[part 1 of 3: packages /EcuInstances to /CommunicationClusters]
AUTOSAR XML (schema 4-2-2)
package /EcuInstances
  ecu instance SRS3: associated-com-i-pdu-group=[RxMPG_ZCUD_CAN1, TxMPG_ZCUD_CAN1, TxMPG_ZCUD_CANFD3], com-configuration-gw-time-base=0.005, com-configuration-rx-time-base=0.005, com-configuration-tx-time-base=0.005, sleep-mode-supported=true, wake-up-over-bus-supported=true
    can communication controller ZCUD_CAN1: wake-up-by-controller-supported=true, can-controller-attributes=can-controller-configuration-requirements={max-number-of-time-quanta-per-bit=22, max-sample-point=86.67, max-sync-jump-width=13.0, min-number-of-time-quanta-per-bit=10, min-sample-point=80.0, min-sync-jump-width=9.0}
    can communication controller ZCUD_CANFD3: can-controller-attributes=can-controller-configuration-requirements={can-controller-fd-requirements={max-number-of-time-quanta-per-bit=40, max-sample-point=70.0, max-sync-jump-width=30.0, min-number-of-time-quanta-per-bit=20, min-sample-point=70.0, min-sync-jump-width=30.0}, max-number-of-time-quanta-per-bit=22, max-sample-point=86.67, max-sync-jump-width=13.0, min-number-of-time-quanta-per-bit=10, min-sample-point=80.0, min-sync-jump-width=9.0}
    can communication connector ZCUD_CAN1_SRS3: comm-controller=ZCUD_CAN1, pnc-wakeup-data-mask=536870912
    can communication connector ZCUD_CANFD3_SRS3: comm-controller=ZCUD_CANFD3, pnc-gateway-type=NONE, pnc-wakeup-data-mask=536870912
package /CommunicationClusters
  can cluster ZCUD_CANFD3: baudrate=500000, protocol-name=CAN, protocol-version=CAN, can-fd-baudrate=2000000
    can physical channel ZCUD_CANFD3: comm-connectors=ZCUD_CANFD3_SRS3
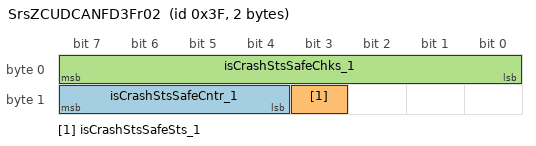
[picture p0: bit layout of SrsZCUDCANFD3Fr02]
      frame SrsZCUDCANFD3Fr02: id 0x3F, from SRS3, frame-length=2, can-addressing-mode=STANDARD, can-fd-frame-support=true, can-frame-tx-behavior=CAN-FD
        pdu SrsZCUDCANFD3SignalIPdu02: length=2, minimum-delay=0.01, transmission-mode-condition{data-filter=data-filter-type=ALWAYS, i-signal-in-i-pdu=igCrashStsSafe_1_mtx}, transmission-mode-true-timing={cyclic-timing={time-offset=0.0, time-period=0.2}, event-controlled-timing=number-of-repetitions=0}, unused-bit-pattern=0
          signal isCrashStsSafeCntr_1: start 15, 4 bit, big-endian, data-type-policy=NETWORK-REPRESENTATION-FROM-COM-SPEC, init-value=0, base-type=UInt4_2, compu-method=UInt4_1, category=VALUE, transfer-property=TRIGGERED  # Counter for E2E
          signal isCrashStsSafeSts_1: start 11, 1 bit, big-endian, data-type-policy=NETWORK-REPRESENTATION-FROM-COM-SPEC, init-value=0, base-type=CrashSts2_2, compu-method=CrashSts2_2, category=VALUE, transfer-property=TRIGGERED  # Information if a crash has been detected by SRS.
          signal isCrashStsSafeChks_1: start 7, 8 bit, big-endian, data-type-policy=NETWORK-REPRESENTATION-FROM-COM-SPEC, init-value=255, base-type=UInt8_2, compu-method=UInt8_1, category=VALUE, transfer-property=TRIGGERED  # Checksum for E2E
          mapping igCrashStsSafe_1_mtx: i-signal-group=igCrashStsSafe_1, packing-byte-order=big-endian, start-position=7, transfer-property=TRIGGERED, update-indication-bit-position=10
      frame SrsZCUDCANFD3VFCVectorFr: id 0x546, from SRS3, frame-length=8, can-addressing-mode=STANDARD, can-fd-frame-support=false, can-frame-tx-behavior=CAN-20
        pdu SrsZCUDCANFD3VFCVectorSignalIPdu: length=8, transmission-mode-condition{data-filter=data-filter-type=ALWAYS, i-signal-in-i-pdu=igVFCVectorSRS_1_mtx}, transmission-mode-true-timing=cyclic-timing={time-offset=0.0, time-period=1.0}, unused-bit-pattern=0
          signal isVFCVectorSRSVFCid9_1: start 12, 1 bit, big-endian, data-type-policy=NETWORK-REPRESENTATION-FROM-COM-SPEC, init-value=0, base-type=VFCOnOff_4, compu-method=VFCOnOff_4, category=VALUE, transfer-property=PENDING  # IPWakeup
          signal isVFCVectorSRSVFCid58_1: start 59, 1 bit, big-endian, data-type-policy=NETWORK-REPRESENTATION-FROM-COM-SPEC, init-value=0, base-type=VFCOnOff_4, compu-method=VFCOnOff_4, category=VALUE, transfer-property=PENDING  # VFC58
          signal isVFCVectorSRSVFCid56_1: start 61, 1 bit, big-endian, data-type-policy=NETWORK-REPRESENTATION-FROM-COM-SPEC, init-value=0, base-type=VFCOnOff_4, compu-method=VFCOnOff_4, category=VALUE, transfer-property=PENDING  # BackboneFlexray
          signal isVFCVectorSRSVFCid41_1: start 44, 1 bit, big-endian, data-type-policy=NETWORK-REPRESENTATION-FROM-COM-SPEC, init-value=0, base-type=VFCOnOff_4, compu-method=VFCOnOff_4, category=VALUE, transfer-property=PENDING  # InfotainmentPush
          signal isVFCVectorSRSVFCid34_1: start 35, 1 bit, big-endian, data-type-policy=NETWORK-REPRESENTATION-FROM-COM-SPEC, init-value=0, base-type=VFCOnOff_4, compu-method=VFCOnOff_4, category=VALUE, transfer-property=PENDING  # VehicleModeManagement
          signal isVFCVectorSRSVFCid2_1: start 3, 1 bit, big-endian, data-type-policy=NETWORK-REPRESENTATION-FROM-COM-SPEC, init-value=0, base-type=VFCOnOff_4, compu-method=VFCOnOff_4, category=VALUE, transfer-property=PENDING  # PostClimatisation
          signal isVFCVectorSRSVFCid50_1: start 51, 1 bit, big-endian, data-type-policy=NETWORK-REPRESENTATION-FROM-COM-SPEC, init-value=0, base-type=VFCOnOff_4, compu-method=VFCOnOff_4, category=VALUE, transfer-property=PENDING  # VFC50
          signal isVFCVectorSRSVFCid39_1: start 46, 1 bit, big-endian, data-type-policy=NETWORK-REPRESENTATION-FROM-COM-SPEC, init-value=0, base-type=VFCOnOff_4, compu-method=VFCOnOff_4, category=VALUE, transfer-property=PENDING  # VFC39
          signal isVFCVectorSRSVFCid53_1: start 48, 1 bit, big-endian, data-type-policy=NETWORK-REPRESENTATION-FROM-COM-SPEC, init-value=0, base-type=VFCOnOff_4, compu-method=VFCOnOff_4, category=VALUE, transfer-property=PENDING  # VisualAssist
          signal isVFCVectorSRSVFCid11_1: start 10, 1 bit, big-endian, data-type-policy=NETWORK-REPRESENTATION-FROM-COM-SPEC, init-value=0, base-type=VFCOnOff_4, compu-method=VFCOnOff_4, category=VALUE, transfer-property=PENDING  # VFC11
          signal isVFCVectorSRSVFCid45_1: start 40, 1 bit, big-endian, data-type-policy=NETWORK-REPRESENTATION-FROM-COM-SPEC, init-value=0, base-type=VFCOnOff_4, compu-method=VFCOnOff_4, category=VALUE, transfer-property=PENDING  # GlobalShortDuration
          signal isVFCVectorSRSVFCid3_1: start 2, 1 bit, big-endian, data-type-policy=NETWORK-REPRESENTATION-FROM-COM-SPEC, init-value=0, base-type=VFCOnOff_4, compu-method=VFCOnOff_4, category=VALUE, transfer-property=PENDING  # PowertrainParkingClimatization
          signal isVFCVectorSRSVFCid10_1: start 11, 1 bit, big-endian, data-type-policy=NETWORK-REPRESENTATION-FROM-COM-SPEC, init-value=0, base-type=VFCOnOff_4, compu-method=VFCOnOff_4, category=VALUE, transfer-property=PENDING  # ExteriorLighting
          signal isVFCVectorSRSVFCid25_1: start 28, 1 bit, big-endian, data-type-policy=NETWORK-REPRESENTATION-FROM-COM-SPEC, init-value=0, base-type=VFCOnOff_4, compu-method=VFCOnOff_4, category=VALUE, transfer-property=PENDING  # SeatComfortFunctions
          signal isVFCVectorSRSVFCid5_1: start 0, 1 bit, big-endian, data-type-policy=NETWORK-REPRESENTATION-FROM-COM-SPEC, init-value=0, base-type=VFCOnOff_4, compu-method=VFCOnOff_4, category=VALUE, transfer-property=PENDING  # VFC5
          signal isVFCVectorSRSVFCid21_1: start 16, 1 bit, big-endian, data-type-policy=NETWORK-REPRESENTATION-FROM-COM-SPEC, init-value=0, base-type=VFCOnOff_4, compu-method=VFCOnOff_4, category=VALUE, transfer-property=PENDING  # PowerClosures
          signal isVFCVectorSRSVFCid12_1: start 9, 1 bit, big-endian, data-type-policy=NETWORK-REPRESENTATION-FROM-COM-SPEC, init-value=0, base-type=VFCOnOff_4, compu-method=VFCOnOff_4, category=VALUE, transfer-property=PENDING  # Alarm
          signal isVFCVectorSRSVFCid54_1: start 63, 1 bit, big-endian, data-type-policy=NETWORK-REPRESENTATION-FROM-COM-SPEC, init-value=0, base-type=VFCOnOff_4, compu-method=VFCOnOff_4, category=VALUE, transfer-property=PENDING  # PassiveSafety
          signal isVFCVectorSRSVFCid47_1: start 54, 1 bit, big-endian, data-type-policy=NETWORK-REPRESENTATION-FROM-COM-SPEC, init-value=0, base-type=VFCOnOff_4, compu-method=VFCOnOff_4, category=VALUE, transfer-property=PENDING  # VFC47
          signal isVFCVectorSRSVFCid38_1: start 47, 1 bit, big-endian, data-type-policy=NETWORK-REPRESENTATION-FROM-COM-SPEC, init-value=0, base-type=VFCOnOff_4, compu-method=VFCOnOff_4, category=VALUE, transfer-property=PENDING  # Visibility
          signal isVFCVectorSRSVFCid42_1: start 43, 1 bit, big-endian, data-type-policy=NETWORK-REPRESENTATION-FROM-COM-SPEC, init-value=0, base-type=VFCOnOff_4, compu-method=VFCOnOff_4, category=VALUE, transfer-property=PENDING  # ChargingHV
          signal isVFCVectorSRSVFCid52_1: start 49, 1 bit, big-endian, data-type-policy=NETWORK-REPRESENTATION-FROM-COM-SPEC, init-value=0, base-type=VFCOnOff_4, compu-method=VFCOnOff_4, category=VALUE, transfer-property=PENDING  # HVBatteryThermalEventWarning
          signal isVFCVectorSRSVFCid24_1: start 29, 1 bit, big-endian, data-type-policy=NETWORK-REPRESENTATION-FROM-COM-SPEC, init-value=0, base-type=VFCOnOff_4, compu-method=VFCOnOff_4, category=VALUE, transfer-property=PENDING  # SettingsProfile
          signal isVFCVectorSRSVFCid60_1: start 57, 1 bit, big-endian, data-type-policy=NETWORK-REPRESENTATION-FROM-COM-SPEC, init-value=0, base-type=VFCOnOff_4, compu-method=VFCOnOff_4, category=VALUE, transfer-property=PENDING  # VFC60
          signal isVFCVectorSRSVFCid57_1: start 60, 1 bit, big-endian, data-type-policy=NETWORK-REPRESENTATION-FROM-COM-SPEC, init-value=0, base-type=VFCOnOff_4, compu-method=VFCOnOff_4, category=VALUE, transfer-property=PENDING  # Functionmarket
          signal isVFCVectorSRSVFCid49_1: start 52, 1 bit, big-endian, data-type-policy=NETWORK-REPRESENTATION-FROM-COM-SPEC, init-value=0, base-type=VFCOnOff_4, compu-method=VFCOnOff_4, category=VALUE, transfer-property=PENDING  # ChargingLVInit
          signal isVFCVectorSRSVFCid19_1: start 18, 1 bit, big-endian, data-type-policy=NETWORK-REPRESENTATION-FROM-COM-SPEC, init-value=0, base-type=VFCOnOff_4, compu-method=VFCOnOff_4, category=VALUE, transfer-property=PENDING  # VFC19
          signal isVFCVectorSRSVFCid4_1: start 1, 1 bit, big-endian, data-type-policy=NETWORK-REPRESENTATION-FROM-COM-SPEC, init-value=0, base-type=VFCOnOff_4, compu-method=VFCOnOff_4, category=VALUE, transfer-property=PENDING  # VFC4
          signal isVFCVectorSRSVFCid20_1: start 17, 1 bit, big-endian, data-type-policy=NETWORK-REPRESENTATION-FROM-COM-SPEC, init-value=0, base-type=VFCOnOff_4, compu-method=VFCOnOff_4, category=VALUE, transfer-property=PENDING  # VFC20
          signal isVFCVectorSRSVFCid8_1: start 13, 1 bit, big-endian, data-type-policy=NETWORK-REPRESENTATION-FROM-COM-SPEC, init-value=0, base-type=VFCOnOff_4, compu-method=VFCOnOff_4, category=VALUE, transfer-property=PENDING  # VFC8
          signal isVFCVectorSRSVFCid27_1: start 26, 1 bit, big-endian, data-type-policy=NETWORK-REPRESENTATION-FROM-COM-SPEC, init-value=0, base-type=VFCOnOff_4, compu-method=VFCOnOff_4, category=VALUE, transfer-property=PENDING  # InfotainmentPoll
          signal isVFCVectorSRSVFCid29_1: start 24, 1 bit, big-endian, data-type-policy=NETWORK-REPRESENTATION-FROM-COM-SPEC, init-value=0, base-type=VFCOnOff_4, compu-method=VFCOnOff_4, category=VALUE, transfer-property=PENDING  # VFC29
          signal isVFCVectorSRSVFCid18_1: start 19, 1 bit, big-endian, data-type-policy=NETWORK-REPRESENTATION-FROM-COM-SPEC, init-value=0, base-type=VFCOnOff_4, compu-method=VFCOnOff_4, category=VALUE, transfer-property=PENDING  # PropulsionStart
          signal isVFCVectorSRSVFCid17_1: start 20, 1 bit, big-endian, data-type-policy=NETWORK-REPRESENTATION-FROM-COM-SPEC, init-value=0, base-type=VFCOnOff_4, compu-method=VFCOnOff_4, category=VALUE, transfer-property=PENDING  # RemoteKeyFunctionality
          signal isVFCVectorSRSVFCid43_1: start 42, 1 bit, big-endian, data-type-policy=NETWORK-REPRESENTATION-FROM-COM-SPEC, init-value=0, base-type=VFCOnOff_4, compu-method=VFCOnOff_4, category=VALUE, transfer-property=PENDING  # BodyPreClimatisation
          signal isVFCVectorSRSVFCid48_1: start 53, 1 bit, big-endian, data-type-policy=NETWORK-REPRESENTATION-FROM-COM-SPEC, init-value=0, base-type=VFCOnOff_4, compu-method=VFCOnOff_4, category=VALUE, transfer-property=PENDING  # DoorOpenWarning
          signal isVFCVectorSRSVFCid33_1: start 36, 1 bit, big-endian, data-type-policy=NETWORK-REPRESENTATION-FROM-COM-SPEC, init-value=0, base-type=VFCOnOff_4, compu-method=VFCOnOff_4, category=VALUE, transfer-property=PENDING  # Diagnostics
          signal isVFCVectorSRSVFCid1_1: start 4, 1 bit, big-endian, data-type-policy=NETWORK-REPRESENTATION-FROM-COM-SPEC, init-value=0, base-type=VFCOnOff_4, compu-method=VFCOnOff_4, category=VALUE, transfer-property=PENDING  # ParkingDrivingClimatization
          signal isVFCVectorSRSVFCid32_1: start 37, 1 bit, big-endian, data-type-policy=NETWORK-REPRESENTATION-FROM-COM-SPEC, init-value=0, base-type=VFCOnOff_4, compu-method=VFCOnOff_4, category=VALUE, transfer-property=PENDING  # VFC32
          signal isVFCVectorSRSBlockID_1: start 7, 2 bit, big-endian, data-type-policy=NETWORK-REPRESENTATION-FROM-COM-SPEC, init-value=0, base-type=BlockID_3, compu-method=BlockID_2, category=VALUE, transfer-property=PENDING  # BlockID
          signal isVFCVectorSRSVFCid51_1: start 50, 1 bit, big-endian, data-type-policy=NETWORK-REPRESENTATION-FROM-COM-SPEC, init-value=0, base-type=VFCOnOff_4, compu-method=VFCOnOff_4, category=VALUE, transfer-property=PENDING  # VFC51
          signal isVFCVectorSRSVFCid36_1: start 33, 1 bit, big-endian, data-type-policy=NETWORK-REPRESENTATION-FROM-COM-SPEC, init-value=0, base-type=VFCOnOff_4, compu-method=VFCOnOff_4, category=VALUE, transfer-property=PENDING  # Immobilizer
          signal isVFCVectorSRSVFCid7_1: start 14, 1 bit, big-endian, data-type-policy=NETWORK-REPRESENTATION-FROM-COM-SPEC, init-value=0, base-type=VFCOnOff_4, compu-method=VFCOnOff_4, category=VALUE, transfer-property=PENDING  # VFC7
          signal isVFCVectorSRSVFCid28_1: start 25, 1 bit, big-endian, data-type-policy=NETWORK-REPRESENTATION-FROM-COM-SPEC, init-value=0, base-type=VFCOnOff_4, compu-method=VFCOnOff_4, category=VALUE, transfer-property=PENDING  # HVEnergyStorage
          signal isVFCVectorSRSVFCid0_1: start 5, 1 bit, big-endian, data-type-policy=NETWORK-REPRESENTATION-FROM-COM-SPEC, init-value=0, base-type=VFCOnOff_4, compu-method=VFCOnOff_4, category=VALUE, transfer-property=PENDING  # SettingsComfort
          signal isVFCVectorSRSVFCid46_1: start 55, 1 bit, big-endian, data-type-policy=NETWORK-REPRESENTATION-FROM-COM-SPEC, init-value=0, base-type=VFCOnOff_4, compu-method=VFCOnOff_4, category=VALUE, transfer-property=PENDING  # ExteriorLightsHazard
          signal isVFCVectorSRSVFCid14_1: start 23, 1 bit, big-endian, data-type-policy=NETWORK-REPRESENTATION-FROM-COM-SPEC, init-value=0, base-type=VFCOnOff_4, compu-method=VFCOnOff_4, category=VALUE, transfer-property=PENDING  # InteriorLighting
          signal isVFCVectorSRSVFCid15_1: start 22, 1 bit, big-endian, data-type-policy=NETWORK-REPRESENTATION-FROM-COM-SPEC, init-value=0, base-type=VFCOnOff_4, compu-method=VFCOnOff_4, category=VALUE, transfer-property=PENDING  # VFC15
          signal isVFCVectorSRSVFCid26_1: start 27, 1 bit, big-endian, data-type-policy=NETWORK-REPRESENTATION-FROM-COM-SPEC, init-value=0, base-type=VFCOnOff_4, compu-method=VFCOnOff_4, category=VALUE, transfer-property=PENDING  # Brake
          signal isVFCVectorSRSVFCid37_1: start 32, 1 bit, big-endian, data-type-policy=NETWORK-REPRESENTATION-FROM-COM-SPEC, init-value=0, base-type=VFCOnOff_4, compu-method=VFCOnOff_4, category=VALUE, transfer-property=PENDING  # Windows
          signal isVFCVectorSRSVFCid13_1: start 8, 1 bit, big-endian, data-type-policy=NETWORK-REPRESENTATION-FROM-COM-SPEC, init-value=0, base-type=VFCOnOff_4, compu-method=VFCOnOff_4, category=VALUE, transfer-property=PENDING  # VFC13
          signal isVFCVectorSRSVFCid30_1: start 39, 1 bit, big-endian, data-type-policy=NETWORK-REPRESENTATION-FROM-COM-SPEC, init-value=0, base-type=VFCOnOff_4, compu-method=VFCOnOff_4, category=VALUE, transfer-property=PENDING  # TelematicsConnectivity
          signal isVFCVectorSRSVFCid55_1: start 62, 1 bit, big-endian, data-type-policy=NETWORK-REPRESENTATION-FROM-COM-SPEC, init-value=0, base-type=VFCOnOff_4, compu-method=VFCOnOff_4, category=VALUE, transfer-property=PENDING  # LifeDetection
          signal isVFCVectorSRSVFCid6_1: start 15, 1 bit, big-endian, data-type-policy=NETWORK-REPRESENTATION-FROM-COM-SPEC, init-value=0, base-type=VFCOnOff_4, compu-method=VFCOnOff_4, category=VALUE, transfer-property=PENDING  # SettingsVehicle
          signal isVFCVectorSRSVFCid35_1: start 34, 1 bit, big-endian, data-type-policy=NETWORK-REPRESENTATION-FROM-COM-SPEC, init-value=0, base-type=VFCOnOff_4, compu-method=VFCOnOff_4, category=VALUE, transfer-property=PENDING  # TrailerCaravanFunctions
          signal isVFCVectorSRSVFCid22_1: start 31, 1 bit, big-endian, data-type-policy=NETWORK-REPRESENTATION-FROM-COM-SPEC, init-value=0, base-type=VFCOnOff_4, compu-method=VFCOnOff_4, category=VALUE, transfer-property=PENDING  # VehicleDriving
          signal isVFCVectorSRSVFCid40_1: start 45, 1 bit, big-endian, data-type-policy=NETWORK-REPRESENTATION-FROM-COM-SPEC, init-value=0, base-type=VFCOnOff_4, compu-method=VFCOnOff_4, category=VALUE, transfer-property=PENDING  # VFC40
          signal isVFCVectorSRSVFCid59_1: start 58, 1 bit, big-endian, data-type-policy=NETWORK-REPRESENTATION-FROM-COM-SPEC, init-value=0, base-type=VFCOnOff_4, compu-method=VFCOnOff_4, category=VALUE, transfer-property=PENDING  # VFC59
          signal isVFCVectorSRSVFCid44_1: start 41, 1 bit, big-endian, data-type-policy=NETWORK-REPRESENTATION-FROM-COM-SPEC, init-value=0, base-type=VFCOnOff_4, compu-method=VFCOnOff_4, category=VALUE, transfer-property=PENDING  # Crash
          signal isVFCVectorSRSVFCid31_1: start 38, 1 bit, big-endian, data-type-policy=NETWORK-REPRESENTATION-FROM-COM-SPEC, init-value=0, base-type=VFCOnOff_4, compu-method=VFCOnOff_4, category=VALUE, transfer-property=PENDING  # VFC31
          signal isVFCVectorSRSVFCid16_1: start 21, 1 bit, big-endian, data-type-policy=NETWORK-REPRESENTATION-FROM-COM-SPEC, init-value=0, base-type=VFCOnOff_4, compu-method=VFCOnOff_4, category=VALUE, transfer-property=PENDING  # Locking
          signal isVFCVectorSRSVFCid61_1: start 56, 1 bit, big-endian, data-type-policy=NETWORK-REPRESENTATION-FROM-COM-SPEC, init-value=0, base-type=VFCOnOff_4, compu-method=VFCOnOff_4, category=VALUE, transfer-property=PENDING  # VFC61
          signal isVFCVectorSRSVFCid23_1: start 30, 1 bit, big-endian, data-type-policy=NETWORK-REPRESENTATION-FROM-COM-SPEC, init-value=0, base-type=VFCOnOff_4, compu-method=VFCOnOff_4, category=VALUE, transfer-property=PENDING  # VFC23
          mapping igVFCVectorSRS_1_mtx: i-signal-group=igVFCVectorSRS_1, packing-byte-order=big-endian, start-position=7, transfer-property=PENDING
      frame SrsZCUDCANFD3Fr01: id 0x32, from SRS3, frame-length=64, can-addressing-mode=STANDARD, can-fd-frame-support=true, can-frame-tx-behavior=CAN-FD
        pdu SrsZCUDCANFD3SignalIPdu01: length=64, transmission-mode-condition{data-filter=data-filter-type=ALWAYS, i-signal-in-i-pdu=igADataRawSafe_1_mtx}, transmission-mode-true-timing=cyclic-timing={time-offset=0.0, time-period=0.005}, unused-bit-pattern=0
          signal isIntgtIMUDataRawSafeYawRateQf: start 300, 2 bit, big-endian, data-type-policy=NETWORK-REPRESENTATION-FROM-COM-SPEC, init-value=1, base-type=Qf1_2, compu-method=Qf1_1, category=VALUE, transfer-property=PENDING  # QF for Yaw rate
          signal isADataRawSafeAVertQf_1: start 71, 2 bit, big-endian, data-type-policy=NETWORK-REPRESENTATION-FROM-COM-SPEC, init-value=1, base-type=Qf1_2, compu-method=Qf1_1, category=VALUE, transfer-property=PENDING  # IMU acceleration data Quality factor for Vertical acceleration
          signal isAsyDataWithCmpSafeGrdtOfALgt_1: start 144, 14 bit, big-endian, data-type-policy=NETWORK-REPRESENTATION-FROM-COM-SPEC, init-value=0, base-type=Jerk1_2, compu-method=Jerk1_1, category=VALUE, transfer-property=PENDING  # IMU processed special data. Derivative of Longitudinal acceleration
          signal isAgDataRawSafeRollRateQf_1: start 115, 2 bit, big-endian, data-type-policy=NETWORK-REPRESENTATION-FROM-COM-SPEC, init-value=1, base-type=Qf1_2, compu-method=Qf1_1, category=VALUE, transfer-property=PENDING  # IMU angular rate data. Quality factor for Roll Rate
          signal isIntgtIMUDataRawSafeRollRateQf: start 302, 2 bit, big-endian, data-type-policy=NETWORK-REPRESENTATION-FROM-COM-SPEC, init-value=1, base-type=Qf1_2, compu-method=Qf1_1, category=VALUE, transfer-property=PENDING  # QF for Roll rate
          signal isIntgtIMUDataRawSafeAvert: start 257, 15 bit, big-endian, data-type-policy=NETWORK-REPRESENTATION-FROM-COM-SPEC, init-value=1155, base-type=A38_2, compu-method=A38_1, category=VALUE, transfer-property=PENDING  # IMU acceleration data Vertical acceleration
          signal isADataRawSafeALat_1: start 6, 15 bit, big-endian, data-type-policy=NETWORK-REPRESENTATION-FROM-COM-SPEC, init-value=0, base-type=A38_2, compu-method=A38_1, category=VALUE, transfer-property=PENDING  # IMU acceleration data Lateral acceleration
          signal isAsyDataWithCmpSafeALgt1Qf_1: start 180, 2 bit, big-endian, data-type-policy=NETWORK-REPRESENTATION-FROM-COM-SPEC, init-value=1, base-type=Qf1_2, compu-method=Qf1_1, category=VALUE, transfer-property=PENDING  # IMU processed special data. Quality factor for Longitudinal acceleration
          signal isAgDataRawSafeYawRateQf_1: start 113, 2 bit, big-endian, data-type-policy=NETWORK-REPRESENTATION-FROM-COM-SPEC, init-value=1, base-type=Qf1_2, compu-method=Qf1_1, category=VALUE, transfer-property=PENDING  # IMU angular rate data. Quality Factor for Yaw Rate
          signal isIntgtIMUDataRawSafeYawRate: start 223, 16 bit, big-endian, data-type-policy=NETWORK-REPRESENTATION-FROM-COM-SPEC, init-value=0, base-type=AgSpd34_2, compu-method=AgSpd34_1, category=VALUE, transfer-property=PENDING  # IMU angular rate Yaw rate
          signal isAsyDataWithCmpSafeALatWithCmp_1: start 143, 15 bit, big-endian, data-type-policy=NETWORK-REPRESENTATION-FROM-COM-SPEC, init-value=0, base-type=A38_2, compu-method=A38_1, category=VALUE, transfer-property=PENDING  # IMU processed special data. Compensated Lateral acceleration
          signal isIntgtIMUDataRawSafeCntr: start 282, 4 bit, big-endian, data-type-policy=NETWORK-REPRESENTATION-FROM-COM-SPEC, init-value=0, base-type=UInt4_2, compu-method=UInt4_1, category=VALUE, transfer-property=PENDING  # Counter
          signal isAsyDataWithCmpSafeALat1Qf_1: start 182, 2 bit, big-endian, data-type-policy=NETWORK-REPRESENTATION-FROM-COM-SPEC, init-value=1, base-type=Qf1_2, compu-method=Qf1_1, category=VALUE, transfer-property=PENDING  # IMU processed special data. Quality factor for Lateral acceleration signal
          signal isAsyDataWithCmpSafeYawRateQf_1: start 178, 2 bit, big-endian, data-type-policy=NETWORK-REPRESENTATION-FROM-COM-SPEC, init-value=1, base-type=Qf1_2, compu-method=Qf1_1, category=VALUE, transfer-property=PENDING  # IMU processed special data. Quality Factor for Yaw Rate
          signal isADataRawSafeAVert_1: start 55, 15 bit, big-endian, data-type-policy=NETWORK-REPRESENTATION-FROM-COM-SPEC, init-value=1155, base-type=A38_2, compu-method=A38_1, category=VALUE, transfer-property=PENDING  # IMU acceleration data Vertical acceleration
          signal isAgDataRawSafeChks_1: start 111, 8 bit, big-endian, data-type-policy=NETWORK-REPRESENTATION-FROM-COM-SPEC, init-value=255, base-type=UInt8_2, compu-method=UInt8_1, category=VALUE, transfer-property=PENDING  # IMU angular rate data. Check summa
          signal isIntgtIMUDataRawSafeRollRate: start 207, 16 bit, big-endian, data-type-policy=NETWORK-REPRESENTATION-FROM-COM-SPEC, init-value=0, base-type=AgSpd34_2, compu-method=AgSpd34_1, category=VALUE, transfer-property=PENDING  # IMU angular rate Roll rate
          signal isADataRawSafeChks_1: start 39, 8 bit, big-endian, data-type-policy=NETWORK-REPRESENTATION-FROM-COM-SPEC, init-value=255, base-type=UInt8_2, compu-method=UInt8_1, category=VALUE, transfer-property=PENDING  # IMU acceleration data Check sum
          signal isADataRawSafeCntr_1: start 47, 4 bit, big-endian, data-type-policy=NETWORK-REPRESENTATION-FROM-COM-SPEC, init-value=0, base-type=UInt4_2, compu-method=UInt4_1, category=VALUE, transfer-property=PENDING  # IMU acceleration data Counter
          signal isIntgtIMUDataRawSafeALat: start 239, 15 bit, big-endian, data-type-policy=NETWORK-REPRESENTATION-FROM-COM-SPEC, init-value=0, base-type=A38_2, compu-method=A38_1, category=VALUE, transfer-property=PENDING  # IMU acceleration data Lateral acceleration
          signal isIntgtIMUDataRawSafeChks: start 274, 8 bit, big-endian, data-type-policy=NETWORK-REPRESENTATION-FROM-COM-SPEC, init-value=255, base-type=UInt8_2, compu-method=UInt8_1, category=VALUE, transfer-property=PENDING  # Check summa
          signal isAsyDataWithCmpSafeCntr_1: start 170, 4 bit, big-endian, data-type-policy=NETWORK-REPRESENTATION-FROM-COM-SPEC, init-value=0, base-type=UInt4_2, compu-method=UInt4_1, category=VALUE, transfer-property=PENDING  # IMU processed special data. Counter
          signal isADataRawSafeALgt_1: start 23, 15 bit, big-endian, data-type-policy=NETWORK-REPRESENTATION-FROM-COM-SPEC, init-value=0, base-type=A38_2, compu-method=A38_1, category=VALUE, transfer-property=PENDING  # IMU acceleration data Longitudinal acceleration
          signal isAsyDataWithCmpSafeYawRateWithCmp_1: start 127, 16 bit, big-endian, data-type-policy=NETWORK-REPRESENTATION-FROM-COM-SPEC, init-value=0, base-type=AgSpd34_2, compu-method=AgSpd34_1, category=VALUE, transfer-property=PENDING  # IMU processed special data. Compensated Yaw rate
          signal isIntgtIMUDataRawSafePitchRateQf: start 288, 2 bit, big-endian, data-type-policy=NETWORK-REPRESENTATION-FROM-COM-SPEC, init-value=1, base-type=Qf1_2, compu-method=Qf1_1, category=VALUE, transfer-property=PENDING  # QF for Pitch rate
          signal isIntgtIMUDataRawSafeALgt1Qf: start 292, 2 bit, big-endian, data-type-policy=NETWORK-REPRESENTATION-FROM-COM-SPEC, init-value=1, base-type=Qf1_2, compu-method=Qf1_1, category=VALUE, transfer-property=PENDING  # QF for Longitudinal acceleration
          signal isAgDataRawSafeCntr_1: start 119, 4 bit, big-endian, data-type-policy=NETWORK-REPRESENTATION-FROM-COM-SPEC, init-value=0, base-type=UInt4_2, compu-method=UInt4_1, category=VALUE, transfer-property=PENDING  # IMU angular rate data. Counter
          signal isIntgtIMUDataRawSafePitchRate: start 191, 16 bit, big-endian, data-type-policy=NETWORK-REPRESENTATION-FROM-COM-SPEC, init-value=0, base-type=AgSpd34_2, compu-method=AgSpd34_1, category=VALUE, transfer-property=PENDING  # IMU angular rate Pitch rate
          signal isIntgtIMUDataRawSafeALat1Qf: start 294, 2 bit, big-endian, data-type-policy=NETWORK-REPRESENTATION-FROM-COM-SPEC, init-value=1, base-type=Qf1_2, compu-method=Qf1_1, category=VALUE, transfer-property=PENDING  # QF for Lateral acceleration
          signal isADataRawSafeALgt1Qf_1: start 41, 2 bit, big-endian, data-type-policy=NETWORK-REPRESENTATION-FROM-COM-SPEC, init-value=1, base-type=Qf1_2, compu-method=Qf1_1, category=VALUE, transfer-property=PENDING  # IMU acceleration data Quality factor for Longitudinal acceleration
          signal isIntgtIMUDataRawSafeALgt: start 240, 15 bit, big-endian, data-type-policy=NETWORK-REPRESENTATION-FROM-COM-SPEC, init-value=0, base-type=A38_2, compu-method=A38_1, category=VALUE, transfer-property=PENDING  # IMU acceleration data Longitudinal acceleration
          signal isADataRawSafeALat1Qf_1: start 43, 2 bit, big-endian, data-type-policy=NETWORK-REPRESENTATION-FROM-COM-SPEC, init-value=1, base-type=Qf1_2, compu-method=Qf1_1, category=VALUE, transfer-property=PENDING  # IMU acceleration data Quality factor for Lateral acceleration signal
          signal isIntgtIMUDataRawSafeAVertQf: start 290, 2 bit, big-endian, data-type-policy=NETWORK-REPRESENTATION-FROM-COM-SPEC, init-value=1, base-type=Qf1_2, compu-method=Qf1_1, category=VALUE, transfer-property=PENDING  # QF for Vertical acceleration
          signal isAgDataRawSafeRollRate_1: start 79, 16 bit, big-endian, data-type-policy=NETWORK-REPRESENTATION-FROM-COM-SPEC, init-value=0, base-type=AgSpd34_2, compu-method=AgSpd34_1, category=VALUE, transfer-property=PENDING  # IMU angular rate data. Roll Rate
          signal isAgDataRawSafeYawRate_1: start 95, 16 bit, big-endian, data-type-policy=NETWORK-REPRESENTATION-FROM-COM-SPEC, init-value=0, base-type=AgSpd34_2, compu-method=AgSpd34_1, category=VALUE, transfer-property=PENDING  # IMU angular rate data. Yaw Rate
          signal isAsyDataWithCmpSafeChks_1: start 162, 8 bit, big-endian, data-type-policy=NETWORK-REPRESENTATION-FROM-COM-SPEC, init-value=255, base-type=UInt8_2, compu-method=UInt8_1, category=VALUE, transfer-property=PENDING  # IMU processed special data. Check sum
          mapping igIntgtIMUDataRawSafe_mtx: i-signal-group=igIntgtIMUDataRawSafe, packing-byte-order=big-endian, start-position=191, transfer-property=PENDING, update-indication-bit-position=298
          mapping igAsyDataWithCmpSafe_1_mtx: i-signal-group=igAsyDataWithCmpSafe_1, packing-byte-order=big-endian, start-position=127, transfer-property=PENDING, update-indication-bit-position=176
          mapping igADataRawSafe_1_mtx: i-signal-group=igADataRawSafe_1, packing-byte-order=big-endian, start-position=6, transfer-property=PENDING, update-indication-bit-position=7
          mapping igAgDataRawSafe_1_mtx: i-signal-group=igAgDataRawSafe_1, packing-byte-order=big-endian, start-position=79, transfer-property=PENDING, update-indication-bit-position=69
      frame SRSZCUDCANFD3NmFr01: id 0x506, from SRS3, frame-length=8, can-addressing-mode=STANDARD, can-fd-frame-support=false, can-frame-tx-behavior=CAN-20
        nm pdu SrsZCUDCANFD3NmPdu1: length=8, unused-bit-pattern=0
          signal isWakeUpReasonsforSRS_1: start 55, 16 bit, big-endian, data-type-policy=NETWORK-REPRESENTATION-FROM-COM-SPEC, init-value=0, base-type=WakeUpReasons_4, compu-method=WakeupReasons_7, transfer-property=PENDING
      frame SrsZCUDCANFD3Fr03: id 0x229, from SRS3, frame-length=64, can-addressing-mode=STANDARD, can-fd-frame-support=true, can-frame-tx-behavior=CAN-FD
        pdu SrsZCUDCANFD3SignalIPdu03: length=64, transmission-mode-condition{data-filter=data-filter-type=ALWAYS, i-signal-in-i-pdu=igAgDataCmpQuality_1_mtx}, transmission-mode-true-timing=cyclic-timing={time-offset=0.0, time-period=0.1}, unused-bit-pattern=0
          signal isAgDataCmpQualityPitchRateCmpQuality_1: start 7, 8 bit, big-endian, data-type-policy=NETWORK-REPRESENTATION-FROM-COM-SPEC, init-value=0, base-type=UInt8_2, compu-method=UInt8_1, category=VALUE, transfer-property=PENDING  # Quality of offset compensation for pitchrate
          signal isAgDataCmpQualityRollRateCmpQuality_1: start 15, 8 bit, big-endian, data-type-policy=NETWORK-REPRESENTATION-FROM-COM-SPEC, init-value=0, base-type=UInt8_2, compu-method=UInt8_1, category=VALUE, transfer-property=PENDING  # Quality of offset compensation for rollrate
          signal isAgDataCmpQualityYawRateCmpQuality_1: start 23, 8 bit, big-endian, data-type-policy=NETWORK-REPRESENTATION-FROM-COM-SPEC, init-value=0, base-type=UInt8_2, compu-method=UInt8_1, category=VALUE, transfer-property=PENDING  # Quality of offset compensation for yawrate
          mapping igAgDataCmpQuality_1_mtx: i-signal-group=igAgDataCmpQuality_1, packing-byte-order=big-endian, start-position=7, transfer-property=PENDING, update-indication-bit-position=31
      frame SUMZCUDCANFD3NmFr01: id 0x525, to SRS3, frame-length=8, can-addressing-mode=STANDARD, can-fd-frame-support=false, can-frame-rx-behavior=CAN-20, rx-identifier-range={lower-can-id=1280, upper-can-id=1343}
        nm pdu SumZCUDCANFD3NmPdu1: length=8, unused-bit-pattern=0
